# f28p65x_analog_subsys_regs register map
Vendor: Texas Instruments
Peripheral module from a debugger description file (folder C2000).
Address unit: 16 bits
Registers are 32-bit, read-write, no defined reset value unless marked. A register's access mark holds for its fields unless they carry their own. Offsets are as the file gives them; lines under a group give offsets from that group; [hi:lo] are bit positions; {n}, {i} and the like mark numbered series; 'fields as' and 'values as' point back to an identical list; <NAME> marks a mode.

## ANALOG_SUBSYS_REGS — ANALOG SUBSYS Registers
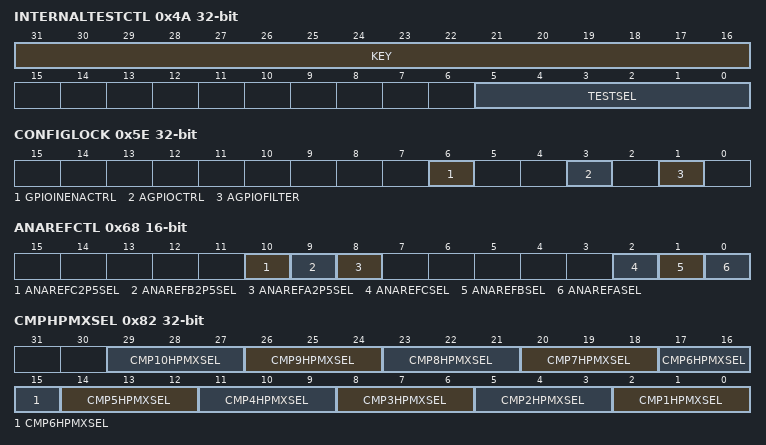
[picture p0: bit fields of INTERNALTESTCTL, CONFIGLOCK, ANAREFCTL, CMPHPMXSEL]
0x4A INTERNALTESTCTL — INTERNALTEST Node Control Register
  [31:16] KEY — Key to Enable writes
  [5:0] TESTSEL — Test Select
0x5E CONFIGLOCK — Lock Register for all the config registers.
  [6] GPIOINENACTRL — Locks all GPIOINENACTRL Register
  [3] AGPIOCTRL — Locks all AGPIOCTRL Register
  [1] AGPIOFILTER — Locks AGPIOFILTER Register
0x60 TSNSCTL 16-bit — Temperature Sensor Control Register
  [0] ENABLE — Temperature Sensor Enable
0x68 ANAREFCTL 16-bit — Analog Reference Control Register.
  [10] ANAREFC2P5SEL — Analog Reference C Select
  [9] ANAREFB2P5SEL — Analog Reference B Select
  [8] ANAREFA2P5SEL — Analog Reference Select
  [2] ANAREFCSEL — Analog Reference C Select
  [1] ANAREFBSEL — Analog Reference B Select
  [0] ANAREFASEL — Analog Reference Select
0x70 VMONCTL 16-bit — Voltage Monitor Control Register
  [8] BORLVMONDIS — Disable BORL(ow) feature on VDDIO
0x82 CMPHPMXSEL — Bits to select one of the many sources on CopmHP inputs. Refer to Pimux diagram for details.
  [3n-1:3n-3] CMP{n}HPMXSEL (n=1..10) — CMP{n}HPMXSEL bits
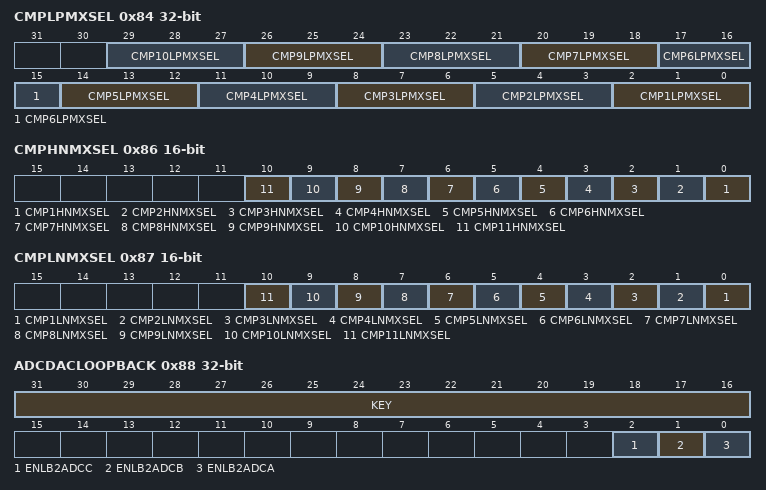
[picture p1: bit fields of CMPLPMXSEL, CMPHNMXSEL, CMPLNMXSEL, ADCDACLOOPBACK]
0x84 CMPLPMXSEL — Bits to select one of the many sources on CopmLP inputs. Refer to Pimux diagram for details.
  [3n-1:3n-3] CMP{n}LPMXSEL (n=1..10) — CMP{n}LPMXSEL bits
0x86 CMPHNMXSEL 16-bit — Bits to select one of the many sources on CopmHN inputs. Refer to Pimux diagram for details.
  [n-1] CMP{n}HNMXSEL (n=1..11) — CMP{n}HNMXSEL bits
0x87 CMPLNMXSEL 16-bit — Bits to select one of the many sources on CopmLN inputs. Refer to Pimux diagram for details.
  [n-1] CMP{n}LNMXSEL (n=1..11) — CMP{n}LNMXSEL bits
0x88 ADCDACLOOPBACK — Enabble loopback from DAC to ADCs
  [31:16] KEY — Key to enable writes
  [2] ENLB2ADCC — Enable COMPDACA loopback to ADCC
  [1] ENLB2ADCB — Enable COMPDACA loopback to ADCB
  [0] ENLB2ADCA — Enable COMPDACA loopback to ADCA
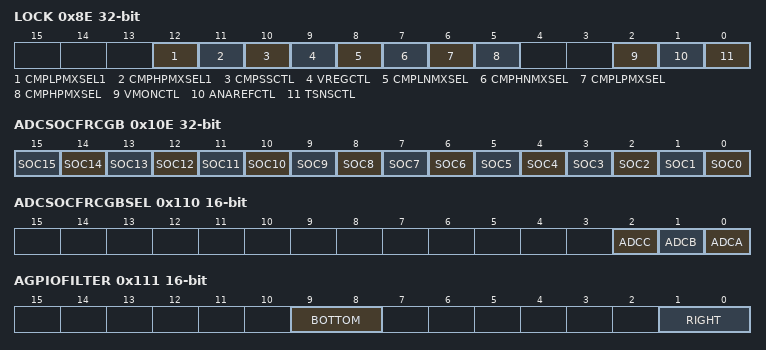
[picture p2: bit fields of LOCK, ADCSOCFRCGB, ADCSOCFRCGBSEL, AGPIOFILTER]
0x8E LOCK
  [12] CMPLPMXSEL1 — CMPLPMXSEL1 Register lock bit
  [11] CMPHPMXSEL1 — CMPHPMXSEL1 Register lock bit
  [10] CMPSSCTL — CMPSSCTL Register lock bit
  [9] VREGCTL — VREGCTL Register lock bit
  [8] CMPLNMXSEL — CMPLNMXSEL Register lock bit
  [7] CMPHNMXSEL — CMPHNMXSEL Register lock bit
  [6] CMPLPMXSEL — CMPLPMXSEL Register lock bit
  [5] CMPHPMXSEL — CMPHPMXSEL Register lock bit
  [2] VMONCTL — VMONCTL Register lock bit
  [1] ANAREFCTL — ANAREFCTL Register lock bit
  [0] TSNSCTL — TSNSCTL Register lock bit
0x90 CMPHPMXSEL1 — Bits to select one of the many sources on CopmHP inputs. Refer to Pimux diagram for details.
  [2:0] CMP11HPMXSEL — CMP15HPMXSEL bits
0x92 CMPLPMXSEL1 — Bits to select one of the many sources on CopmLP inputs. Refer to Pimux diagram for details.
  [2:0] CMP11LPMXSEL — CMP15LPMXSEL bits
0x10E ADCSOCFRCGB — ADC Global SOC Force
  [n] SOC{n} (n=0..15) — Generate synchronous SW trigger for SOC{n}
0x110 ADCSOCFRCGBSEL 16-bit — ADC Global SOC Force Select
  [2] ADCC — Generate synchronous SW trigger for ADCC
  [1] ADCB — Generate synchronous SW trigger for ADCB
  [0] ADCA — Generate synchronous SW trigger for ADCA
0x111 AGPIOFILTER 16-bit — AGPIO Filter Control Register
  [9:8] BOTTOM — AGPIOFILTER Control for bottom side pins
  [1:0] RIGHT — AGPIOFILTER Control for right side pins
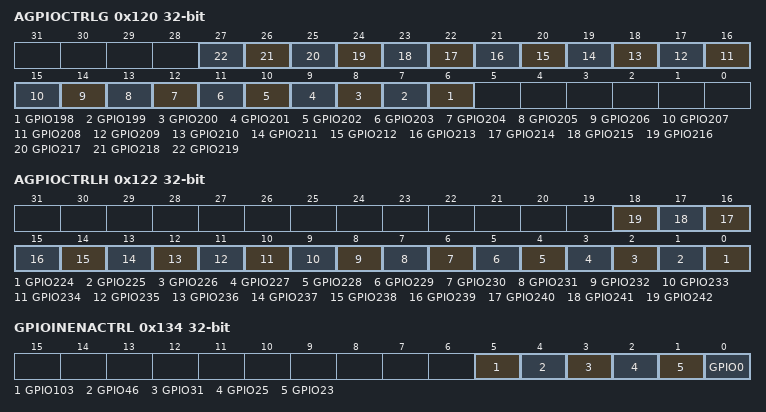
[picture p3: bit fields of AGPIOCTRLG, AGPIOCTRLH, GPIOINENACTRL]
0x120 AGPIOCTRLG — AGPIO Control Register
  [n-192] GPIO{n} (n=198..219) — AGPIOCTRL for GPIO{n}
0x122 AGPIOCTRLH — AGPIO Control Register
  [n-224] GPIO{n} (n=224..242) — AGPIOCTRL for GPIO{n}
0x134 GPIOINENACTRL — GPIOINENACTRL Control Register
  [5] GPIO103 — Input Buffer Control for GPIO103
  [4] GPIO46 — Input Buffer Control for GPIO46
  [3] GPIO31 — Input Buffer Control for GPIO31
  [2] GPIO25 — Input Buffer Control for GPIO25
  [1] GPIO23 — Input Buffer Control for GPIO23
  [0] GPIO0 — Input Buffer Control for GPIO0
